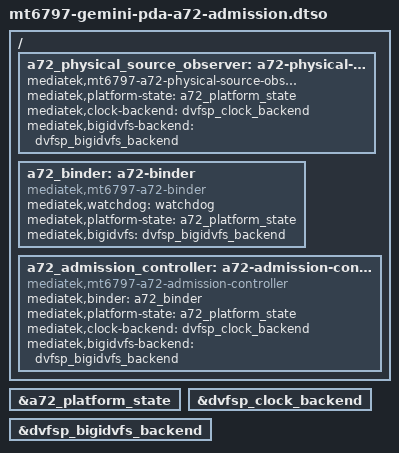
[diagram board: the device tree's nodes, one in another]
// SPDX-License-Identifier: GPL-2.0-only
/* One-shot CPU8 admission overlay for the Gemini serviceability base DT. */

/dts-v1/;
/plugin/;

/ {
	fragment@0 {
		target-path = "/";

		__overlay__ {
			a72_physical_source_observer: a72-physical-source-observer {
				compatible = "mediatek,mt6797-a72-physical-source-observer";
				mediatek,platform-state = <&a72_platform_state>;
				mediatek,clock-backend = <&dvfsp_clock_backend>;
				mediatek,bigidvfs-backend = <&dvfsp_bigidvfs_backend>;
				status = "okay";
			};

			a72_binder: a72-binder {
				compatible = "mediatek,mt6797-a72-binder";
				mediatek,watchdog = <&watchdog>;
				mediatek,platform-state = <&a72_platform_state>;
				mediatek,bigidvfs = <&dvfsp_bigidvfs_backend>;
				status = "okay";
			};

			a72_admission_controller: a72-admission-controller {
				compatible = "mediatek,mt6797-a72-admission-controller";
				mediatek,binder = <&a72_binder>;
				mediatek,platform-state = <&a72_platform_state>;
				mediatek,clock-backend = <&dvfsp_clock_backend>;
				mediatek,bigidvfs-backend = <&dvfsp_bigidvfs_backend>;
				status = "okay";
			};
		};
	};

	fragment@1 {
		target = <&a72_platform_state>;
		__overlay__ { status = "okay"; };
	};

	fragment@2 {
		target = <&dvfsp_clock_backend>;
		__overlay__ { status = "okay"; };
	};

	fragment@3 {
		target = <&dvfsp_bigidvfs_backend>;
		__overlay__ { status = "okay"; };
	};
};
